AUTOSAR XML (schema 4-0-3)
package /Svc_IoHwAb/CompuMethods
  compu method IoHwAb_Cm_EdgeEnum: 1=IOHWAB_RISING_EDGE (IoHwAb_RisingEdge), 2=IOHWAB_FALLING_EDGE (IoHwAb_FallingEdge), 3=IOHWAB_BOTH_EDGES (IoHwAb_BothEdges)
package /Svc_IoHwAb/ImplementationDataTypes
  19 x impl type:
    IoHwAb_LevelType: category=VALUE, base-type=uint8, compu {0=IOHWAB_LOW (IoHwAb_Low), 1=IOHWAB_HIGH (IoHwAb_High)}
    IoHwAb_ThresholdType: category=VALUE, base-type=uint8
    IoHwAb_IndexType: category=VALUE, base-type=uint16
    IoHwAb_PwmEdgeType: category=VALUE, base-type=uint8, compu-method=IoHwAb_Cm_EdgeEnum
    IoHwAb_GptValueType: category=VALUE, base-type=uint32
    IoHwAb_IcuActivationType: category=VALUE, base-type=uint8, compu-method=IoHwAb_Cm_EdgeEnum
    IoHwAb_ValueType: category=VALUE, base-type=uint16
    IoHwAb_IcuEdgeNumberType: category=VALUE, base-type=uint32
    IoHwAb_IcuStateType: category=VALUE, base-type=uint8, compu {0=IOHWAB_IDLE (IoHwAb_Idle), 1=IOHWAB_ACTIVE (IoHwAb_Active)}
    IoHwAb_OcuValueType: category=VALUE, base-type=uint16
    IoHwAb_OcuPinActionType: category=VALUE, base-type=uint8
    IoHwAb_OcuPinStateType: category=VALUE, base-type=uint8
    IoHwAb_LengthType: category=VALUE, base-type=uint8
    IoHwAb_IcuIndexType: category=VALUE, base-type=uint16
    IoHwAb_PwmPeriodType: category=VALUE, base-type=uint32
    IoHwAb_OcuReturnType: category=VALUE, base-type=uint8
    IoHwAb_BoolType: category=VALUE, base-type=uint8, compu {0=IOHWAB_FALSE (IoHwAb_False), 1=IOHWAB_TRUE (IoHwAb_True)}
    IoHwAb_IcuValueType: category=VALUE, base-type=uint32
    IoHwAb_IcuDutyCycleType: category=STRUCTURE
      element ActiveTime: implementation-data-type=IoHwAb_IcuValueType
      element PeriodTime: implementation-data-type=IoHwAb_IcuValueType
package /Svc_IoHwAb/ClientServerInterfaces
  4 x client server interface, all with is-service=true:
    IoHwAb_If_DigDir
      6 x operation:
        ReadDirect
          arg Level: type=IoHwAb_LevelType, direction=OUT, server-argument-impl-policy=USE-ARGUMENT-TYPE
        WriteDirect
          arg Level: type=IoHwAb_LevelType, direction=IN, server-argument-impl-policy=USE-ARGUMENT-TYPE
        SetToInput
        SetToOutput
        IsInput
          arg blResult: type=IoHwAb_BoolType, direction=OUT, server-argument-impl-policy=USE-ARGUMENT-TYPE
        IsOutput
          arg blResult: type=IoHwAb_BoolType, direction=OUT, server-argument-impl-policy=USE-ARGUMENT-TYPE
    IoHwAb_If_AnaInDir
      operation ReadDirect: possible-error=[E_BUSY, E_WRONG_LENGTH, E_SETUP_BUFFER_FAIL]
        arg Value: type=IoHwAb_ValueType, direction=OUT, server-argument-impl-policy=USE-ARGUMENT-TYPE
        arg AnaInDirLength: type=IoHwAb_LengthType, direction=IN, server-argument-impl-policy=USE-ARGUMENT-TYPE
      error E_BUSY: error-code=4
      error E_WRONG_LENGTH: error-code=5
      error E_SETUP_BUFFER_FAIL: error-code=6
    IoHwAb_If_Gpt
      7 x operation:
        StartTimer: possible-error=IoHwAb_If_Gpt/E_NOT_SUPPORTED
          arg Value: type=IoHwAb_GptValueType, direction=IN, server-argument-impl-policy=USE-ARGUMENT-TYPE
        StopTimer: possible-error=IoHwAb_If_Gpt/E_NOT_SUPPORTED
        GetTimeElapsed: possible-error=IoHwAb_If_Gpt/E_NOT_SUPPORTED
          arg Value: type=IoHwAb_GptValueType, direction=OUT, server-argument-impl-policy=USE-ARGUMENT-TYPE
        GetTimeRemaining: possible-error=IoHwAb_If_Gpt/E_NOT_SUPPORTED
          arg Value: type=IoHwAb_GptValueType, direction=OUT, server-argument-impl-policy=USE-ARGUMENT-TYPE
        DisableNotification: possible-error=IoHwAb_If_Gpt/E_NOT_SUPPORTED
        EnableNotification: possible-error=IoHwAb_If_Gpt/E_NOT_SUPPORTED
        Notification
      error E_NOT_SUPPORTED: error-code=10
    IoHwAb_If_Pwm
      6 x operation, all with possible-error=IoHwAb_If_Pwm/E_NOT_SUPPORTED:
        SetDutyCycle
          arg Duty: type=uint16, direction=IN, server-argument-impl-policy=USE-ARGUMENT-TYPE
        SetPeriodAndDuty
          arg Period: type=IoHwAb_PwmPeriodType, direction=IN, server-argument-impl-policy=USE-ARGUMENT-TYPE
          arg Duty: type=uint16, direction=IN, server-argument-impl-policy=USE-ARGUMENT-TYPE
        SetOutputToIdle
        GetOutputState
          arg Level: type=IoHwAb_LevelType, direction=OUT, server-argument-impl-policy=USE-ARGUMENT-TYPE
        DisableNotification
        EnableNotification
          arg NotificationEdge: type=IoHwAb_PwmEdgeType, direction=IN, server-argument-impl-policy=USE-ARGUMENT-TYPE
      error E_NOT_SUPPORTED: error-code=11
package /Svc_IoHwAb/EcuAbstractionSwComponentTypes
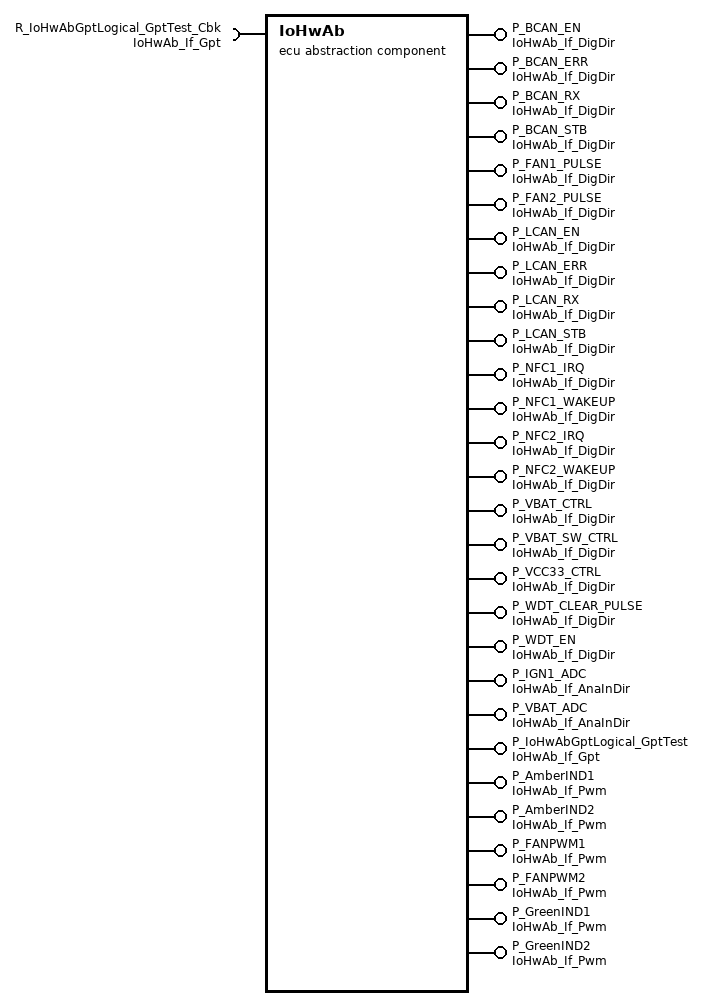
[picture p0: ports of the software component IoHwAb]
  ecu abstraction sw component type IoHwAb
    22 x provide port:
      P_BCAN_EN: provided-interface=IoHwAb_If_DigDir
        provided-com-specs:
          operation=IoHwAb_If_DigDir/ReadDirect, queue-length=1
          operation=WriteDirect, queue-length=1
          operation=SetToInput, queue-length=1
          operation=SetToOutput, queue-length=1
          operation=IsInput, queue-length=1
          operation=IsOutput, queue-length=1
      P_BCAN_ERR: provided-interface=IoHwAb_If_DigDir
        provided-com-specs:
          operation=IoHwAb_If_DigDir/ReadDirect, queue-length=1
          operation=WriteDirect, queue-length=1
          operation=SetToInput, queue-length=1
          operation=SetToOutput, queue-length=1
          operation=IsInput, queue-length=1
          operation=IsOutput, queue-length=1
      P_BCAN_RX: provided-interface=IoHwAb_If_DigDir
        provided-com-specs:
          operation=IoHwAb_If_DigDir/ReadDirect, queue-length=1
          operation=WriteDirect, queue-length=1
          operation=SetToInput, queue-length=1
          operation=SetToOutput, queue-length=1
          operation=IsInput, queue-length=1
          operation=IsOutput, queue-length=1
      P_BCAN_STB: provided-interface=IoHwAb_If_DigDir
        provided-com-specs:
          operation=IoHwAb_If_DigDir/ReadDirect, queue-length=1
          operation=WriteDirect, queue-length=1
          operation=SetToInput, queue-length=1
          operation=SetToOutput, queue-length=1
          operation=IsInput, queue-length=1
          operation=IsOutput, queue-length=1
      P_FAN1_PULSE: provided-interface=IoHwAb_If_DigDir
        provided-com-specs:
          operation=IoHwAb_If_DigDir/ReadDirect, queue-length=1
          operation=WriteDirect, queue-length=1
          operation=SetToInput, queue-length=1
          operation=SetToOutput, queue-length=1
          operation=IsInput, queue-length=1
          operation=IsOutput, queue-length=1
      P_FAN2_PULSE: provided-interface=IoHwAb_If_DigDir
        provided-com-specs:
          operation=IoHwAb_If_DigDir/ReadDirect, queue-length=1
          operation=WriteDirect, queue-length=1
          operation=SetToInput, queue-length=1
          operation=SetToOutput, queue-length=1
          operation=IsInput, queue-length=1
          operation=IsOutput, queue-length=1
      P_LCAN_EN: provided-interface=IoHwAb_If_DigDir
        provided-com-specs:
          operation=IoHwAb_If_DigDir/ReadDirect, queue-length=1
          operation=WriteDirect, queue-length=1
          operation=SetToInput, queue-length=1
          operation=SetToOutput, queue-length=1
          operation=IsInput, queue-length=1
          operation=IsOutput, queue-length=1
      P_LCAN_ERR: provided-interface=IoHwAb_If_DigDir
        provided-com-specs:
          operation=IoHwAb_If_DigDir/ReadDirect, queue-length=1
          operation=WriteDirect, queue-length=1
          operation=SetToInput, queue-length=1
          operation=SetToOutput, queue-length=1
          operation=IsInput, queue-length=1
          operation=IsOutput, queue-length=1
      P_LCAN_RX: provided-interface=IoHwAb_If_DigDir
        provided-com-specs:
          operation=IoHwAb_If_DigDir/ReadDirect, queue-length=1
          operation=WriteDirect, queue-length=1
          operation=SetToInput, queue-length=1
          operation=SetToOutput, queue-length=1
          operation=IsInput, queue-length=1
          operation=IsOutput, queue-length=1
      P_LCAN_STB: provided-interface=IoHwAb_If_DigDir
        provided-com-specs:
          operation=IoHwAb_If_DigDir/ReadDirect, queue-length=1
          operation=WriteDirect, queue-length=1
          operation=SetToInput, queue-length=1
          operation=SetToOutput, queue-length=1
          operation=IsInput, queue-length=1
          operation=IsOutput, queue-length=1
      P_NFC1_IRQ: provided-interface=IoHwAb_If_DigDir
        provided-com-specs:
          operation=IoHwAb_If_DigDir/ReadDirect, queue-length=1
          operation=WriteDirect, queue-length=1
          operation=SetToInput, queue-length=1
          operation=SetToOutput, queue-length=1
          operation=IsInput, queue-length=1
          operation=IsOutput, queue-length=1
      P_NFC1_WAKEUP: provided-interface=IoHwAb_If_DigDir
        provided-com-specs:
          operation=IoHwAb_If_DigDir/ReadDirect, queue-length=1
          operation=WriteDirect, queue-length=1
          operation=SetToInput, queue-length=1
          operation=SetToOutput, queue-length=1
          operation=IsInput, queue-length=1
          operation=IsOutput, queue-length=1
      P_NFC2_IRQ: provided-interface=IoHwAb_If_DigDir
        provided-com-specs:
          operation=IoHwAb_If_DigDir/ReadDirect, queue-length=1
          operation=WriteDirect, queue-length=1
          operation=SetToInput, queue-length=1
          operation=SetToOutput, queue-length=1
          operation=IsInput, queue-length=1
          operation=IsOutput, queue-length=1
      P_NFC2_WAKEUP: provided-interface=IoHwAb_If_DigDir
        provided-com-specs:
          operation=IoHwAb_If_DigDir/ReadDirect, queue-length=1
          operation=WriteDirect, queue-length=1
          operation=SetToInput, queue-length=1
          operation=SetToOutput, queue-length=1
          operation=IsInput, queue-length=1
          operation=IsOutput, queue-length=1
      P_VBAT_CTRL: provided-interface=IoHwAb_If_DigDir
        provided-com-specs:
          operation=IoHwAb_If_DigDir/ReadDirect, queue-length=1
          operation=WriteDirect, queue-length=1
          operation=SetToInput, queue-length=1
          operation=SetToOutput, queue-length=1
          operation=IsInput, queue-length=1
          operation=IsOutput, queue-length=1
      P_VBAT_SW_CTRL: provided-interface=IoHwAb_If_DigDir
        provided-com-specs:
          operation=IoHwAb_If_DigDir/ReadDirect, queue-length=1
          operation=WriteDirect, queue-length=1
          operation=SetToInput, queue-length=1
          operation=SetToOutput, queue-length=1
          operation=IsInput, queue-length=1
          operation=IsOutput, queue-length=1
      P_VCC33_CTRL: provided-interface=IoHwAb_If_DigDir
        provided-com-specs:
          operation=IoHwAb_If_DigDir/ReadDirect, queue-length=1
          operation=WriteDirect, queue-length=1
          operation=SetToInput, queue-length=1
          operation=SetToOutput, queue-length=1
          operation=IsInput, queue-length=1
          operation=IsOutput, queue-length=1
      P_WDT_CLEAR_PULSE: provided-interface=IoHwAb_If_DigDir
        provided-com-specs:
          operation=IoHwAb_If_DigDir/ReadDirect, queue-length=1
          operation=WriteDirect, queue-length=1
          operation=SetToInput, queue-length=1
          operation=SetToOutput, queue-length=1
          operation=IsInput, queue-length=1
          operation=IsOutput, queue-length=1
      P_WDT_EN: provided-interface=IoHwAb_If_DigDir
        provided-com-specs:
          operation=IoHwAb_If_DigDir/ReadDirect, queue-length=1
          operation=WriteDirect, queue-length=1
          operation=SetToInput, queue-length=1
          operation=SetToOutput, queue-length=1
          operation=IsInput, queue-length=1
          operation=IsOutput, queue-length=1
      P_IGN1_ADC: server-com-spec{operation=IoHwAb_If_AnaInDir/ReadDirect, queue-length=1}, provided-interface=IoHwAb_If_AnaInDir
      P_VBAT_ADC: server-com-spec{operation=IoHwAb_If_AnaInDir/ReadDirect, queue-length=1}, provided-interface=IoHwAb_If_AnaInDir
      P_IoHwAbGptLogical_GptTest: provided-interface=IoHwAb_If_Gpt
        provided-com-specs:
          operation=StartTimer, queue-length=1
          operation=StopTimer, queue-length=1
          operation=GetTimeElapsed, queue-length=1
          operation=GetTimeRemaining, queue-length=1
          operation=IoHwAb_If_Gpt/DisableNotification, queue-length=1
          operation=IoHwAb_If_Gpt/EnableNotification, queue-length=1
    require port R_IoHwAbGptLogical_GptTest_Cbk: client-com-spec=Notification, required-interface=IoHwAb_If_Gpt
    6 x provide port, all with provided-interface=IoHwAb_If_Pwm:
      P_AmberIND1
        provided-com-specs:
          operation=SetDutyCycle, queue-length=1
          operation=SetPeriodAndDuty, queue-length=1
          operation=SetOutputToIdle, queue-length=1
          operation=GetOutputState, queue-length=1
          operation=IoHwAb_If_Pwm/DisableNotification, queue-length=1
          operation=IoHwAb_If_Pwm/EnableNotification, queue-length=1
      P_AmberIND2
        provided-com-specs:
          operation=SetDutyCycle, queue-length=1
          operation=SetPeriodAndDuty, queue-length=1
          operation=SetOutputToIdle, queue-length=1
          operation=GetOutputState, queue-length=1
          operation=IoHwAb_If_Pwm/DisableNotification, queue-length=1
          operation=IoHwAb_If_Pwm/EnableNotification, queue-length=1
      P_FANPWM1
        provided-com-specs:
          operation=SetDutyCycle, queue-length=1
          operation=SetPeriodAndDuty, queue-length=1
          operation=SetOutputToIdle, queue-length=1
          operation=GetOutputState, queue-length=1
          operation=IoHwAb_If_Pwm/DisableNotification, queue-length=1
          operation=IoHwAb_If_Pwm/EnableNotification, queue-length=1
      P_FANPWM2
        provided-com-specs:
          operation=SetDutyCycle, queue-length=1
          operation=SetPeriodAndDuty, queue-length=1
          operation=SetOutputToIdle, queue-length=1
          operation=GetOutputState, queue-length=1
          operation=IoHwAb_If_Pwm/DisableNotification, queue-length=1
          operation=IoHwAb_If_Pwm/EnableNotification, queue-length=1
      P_GreenIND1
        provided-com-specs:
          operation=SetDutyCycle, queue-length=1
          operation=SetPeriodAndDuty, queue-length=1
          operation=SetOutputToIdle, queue-length=1
          operation=GetOutputState, queue-length=1
          operation=IoHwAb_If_Pwm/DisableNotification, queue-length=1
          operation=IoHwAb_If_Pwm/EnableNotification, queue-length=1
      P_GreenIND2
        provided-com-specs:
          operation=SetDutyCycle, queue-length=1
          operation=SetPeriodAndDuty, queue-length=1
          operation=SetOutputToIdle, queue-length=1
          operation=GetOutputState, queue-length=1
          operation=IoHwAb_If_Pwm/DisableNotification, queue-length=1
          operation=IoHwAb_If_Pwm/EnableNotification, queue-length=1
    behavior IB_IoHwAb
      158 x operation invoked event:
        IoHwAb_Ev_BCAN_EN_ReadDirect: start-on-event=IoHwAb_Re_DigDir_ReadDirect, operation=P_BCAN_EN.ReadDirect
        IoHwAb_Ev_BCAN_EN_WriteDirect: start-on-event=IoHwAb_Re_DigDir_WriteDirect, operation=P_BCAN_EN.WriteDirect
        IoHwAb_Ev_BCAN_EN_SetToInput: start-on-event=IoHwAb_Re_DigDir_SetToInput, operation=P_BCAN_EN.SetToInput
        IoHwAb_Ev_BCAN_EN_SetToOutput: start-on-event=IoHwAb_Re_DigDir_SetToOutput, operation=P_BCAN_EN.SetToOutput
        IoHwAb_Ev_BCAN_EN_IsInput: start-on-event=IoHwAb_Re_DigDir_IsInput, operation=P_BCAN_EN.IsInput
        IoHwAb_Ev_BCAN_EN_IsOutput: start-on-event=IoHwAb_Re_DigDir_IsOutput, operation=P_BCAN_EN.IsOutput
        IoHwAb_Ev_BCAN_ERR_ReadDirect: start-on-event=IoHwAb_Re_DigDir_ReadDirect, operation=P_BCAN_ERR.ReadDirect
        IoHwAb_Ev_BCAN_ERR_WriteDirect: start-on-event=IoHwAb_Re_DigDir_WriteDirect, operation=P_BCAN_ERR.WriteDirect
        IoHwAb_Ev_BCAN_ERR_SetToInput: start-on-event=IoHwAb_Re_DigDir_SetToInput, operation=P_BCAN_ERR.SetToInput
        IoHwAb_Ev_BCAN_ERR_SetToOutput: start-on-event=IoHwAb_Re_DigDir_SetToOutput, operation=P_BCAN_ERR.SetToOutput
        IoHwAb_Ev_BCAN_ERR_IsInput: start-on-event=IoHwAb_Re_DigDir_IsInput, operation=P_BCAN_ERR.IsInput
        IoHwAb_Ev_BCAN_ERR_IsOutput: start-on-event=IoHwAb_Re_DigDir_IsOutput, operation=P_BCAN_ERR.IsOutput
        IoHwAb_Ev_BCAN_RX_ReadDirect: start-on-event=IoHwAb_Re_DigDir_ReadDirect, operation=P_BCAN_RX.ReadDirect
        IoHwAb_Ev_BCAN_RX_WriteDirect: start-on-event=IoHwAb_Re_DigDir_WriteDirect, operation=P_BCAN_RX.WriteDirect
        IoHwAb_Ev_BCAN_RX_SetToInput: start-on-event=IoHwAb_Re_DigDir_SetToInput, operation=P_BCAN_RX.SetToInput
        IoHwAb_Ev_BCAN_RX_SetToOutput: start-on-event=IoHwAb_Re_DigDir_SetToOutput, operation=P_BCAN_RX.SetToOutput
        IoHwAb_Ev_BCAN_RX_IsInput: start-on-event=IoHwAb_Re_DigDir_IsInput, operation=P_BCAN_RX.IsInput
        IoHwAb_Ev_BCAN_RX_IsOutput: start-on-event=IoHwAb_Re_DigDir_IsOutput, operation=P_BCAN_RX.IsOutput
        IoHwAb_Ev_BCAN_STB_ReadDirect: start-on-event=IoHwAb_Re_DigDir_ReadDirect, operation=P_BCAN_STB.ReadDirect
        IoHwAb_Ev_BCAN_STB_WriteDirect: start-on-event=IoHwAb_Re_DigDir_WriteDirect, operation=P_BCAN_STB.WriteDirect
        IoHwAb_Ev_BCAN_STB_SetToInput: start-on-event=IoHwAb_Re_DigDir_SetToInput, operation=P_BCAN_STB.SetToInput
        IoHwAb_Ev_BCAN_STB_SetToOutput: start-on-event=IoHwAb_Re_DigDir_SetToOutput, operation=P_BCAN_STB.SetToOutput
        IoHwAb_Ev_BCAN_STB_IsInput: start-on-event=IoHwAb_Re_DigDir_IsInput, operation=P_BCAN_STB.IsInput
        IoHwAb_Ev_BCAN_STB_IsOutput: start-on-event=IoHwAb_Re_DigDir_IsOutput, operation=P_BCAN_STB.IsOutput
        IoHwAb_Ev_FAN1_PULSE_ReadDirect: start-on-event=IoHwAb_Re_DigDir_ReadDirect, operation=P_FAN1_PULSE.ReadDirect
        IoHwAb_Ev_FAN1_PULSE_WriteDirect: start-on-event=IoHwAb_Re_DigDir_WriteDirect, operation=P_FAN1_PULSE.WriteDirect
        IoHwAb_Ev_FAN1_PULSE_SetToInput: start-on-event=IoHwAb_Re_DigDir_SetToInput, operation=P_FAN1_PULSE.SetToInput
        IoHwAb_Ev_FAN1_PULSE_SetToOutput: start-on-event=IoHwAb_Re_DigDir_SetToOutput, operation=P_FAN1_PULSE.SetToOutput
        IoHwAb_Ev_FAN1_PULSE_IsInput: start-on-event=IoHwAb_Re_DigDir_IsInput, operation=P_FAN1_PULSE.IsInput
        IoHwAb_Ev_FAN1_PULSE_IsOutput: start-on-event=IoHwAb_Re_DigDir_IsOutput, operation=P_FAN1_PULSE.IsOutput
        IoHwAb_Ev_FAN2_PULSE_ReadDirect: start-on-event=IoHwAb_Re_DigDir_ReadDirect, operation=P_FAN2_PULSE.ReadDirect
        IoHwAb_Ev_FAN2_PULSE_WriteDirect: start-on-event=IoHwAb_Re_DigDir_WriteDirect, operation=P_FAN2_PULSE.WriteDirect
        IoHwAb_Ev_FAN2_PULSE_SetToInput: start-on-event=IoHwAb_Re_DigDir_SetToInput, operation=P_FAN2_PULSE.SetToInput
        IoHwAb_Ev_FAN2_PULSE_SetToOutput: start-on-event=IoHwAb_Re_DigDir_SetToOutput, operation=P_FAN2_PULSE.SetToOutput
        IoHwAb_Ev_FAN2_PULSE_IsInput: start-on-event=IoHwAb_Re_DigDir_IsInput, operation=P_FAN2_PULSE.IsInput
        IoHwAb_Ev_FAN2_PULSE_IsOutput: start-on-event=IoHwAb_Re_DigDir_IsOutput, operation=P_FAN2_PULSE.IsOutput
        IoHwAb_Ev_LCAN_EN_ReadDirect: start-on-event=IoHwAb_Re_DigDir_ReadDirect, operation=P_LCAN_EN.ReadDirect
        IoHwAb_Ev_LCAN_EN_WriteDirect: start-on-event=IoHwAb_Re_DigDir_WriteDirect, operation=P_LCAN_EN.WriteDirect
        IoHwAb_Ev_LCAN_EN_SetToInput: start-on-event=IoHwAb_Re_DigDir_SetToInput, operation=P_LCAN_EN.SetToInput
        IoHwAb_Ev_LCAN_EN_SetToOutput: start-on-event=IoHwAb_Re_DigDir_SetToOutput, operation=P_LCAN_EN.SetToOutput
        IoHwAb_Ev_LCAN_EN_IsInput: start-on-event=IoHwAb_Re_DigDir_IsInput, operation=P_LCAN_EN.IsInput
        IoHwAb_Ev_LCAN_EN_IsOutput: start-on-event=IoHwAb_Re_DigDir_IsOutput, operation=P_LCAN_EN.IsOutput
        IoHwAb_Ev_LCAN_ERR_ReadDirect: start-on-event=IoHwAb_Re_DigDir_ReadDirect, operation=P_LCAN_ERR.ReadDirect
        IoHwAb_Ev_LCAN_ERR_WriteDirect: start-on-event=IoHwAb_Re_DigDir_WriteDirect, operation=P_LCAN_ERR.WriteDirect
        IoHwAb_Ev_LCAN_ERR_SetToInput: start-on-event=IoHwAb_Re_DigDir_SetToInput, operation=P_LCAN_ERR.SetToInput
        IoHwAb_Ev_LCAN_ERR_SetToOutput: start-on-event=IoHwAb_Re_DigDir_SetToOutput, operation=P_LCAN_ERR.SetToOutput
        IoHwAb_Ev_LCAN_ERR_IsInput: start-on-event=IoHwAb_Re_DigDir_IsInput, operation=P_LCAN_ERR.IsInput
        IoHwAb_Ev_LCAN_ERR_IsOutput: start-on-event=IoHwAb_Re_DigDir_IsOutput, operation=P_LCAN_ERR.IsOutput
        IoHwAb_Ev_LCAN_RX_ReadDirect: start-on-event=IoHwAb_Re_DigDir_ReadDirect, operation=P_LCAN_RX.ReadDirect
        IoHwAb_Ev_LCAN_RX_WriteDirect: start-on-event=IoHwAb_Re_DigDir_WriteDirect, operation=P_LCAN_RX.WriteDirect
        IoHwAb_Ev_LCAN_RX_SetToInput: start-on-event=IoHwAb_Re_DigDir_SetToInput, operation=P_LCAN_RX.SetToInput
        IoHwAb_Ev_LCAN_RX_SetToOutput: start-on-event=IoHwAb_Re_DigDir_SetToOutput, operation=P_LCAN_RX.SetToOutput
        IoHwAb_Ev_LCAN_RX_IsInput: start-on-event=IoHwAb_Re_DigDir_IsInput, operation=P_LCAN_RX.IsInput
        IoHwAb_Ev_LCAN_RX_IsOutput: start-on-event=IoHwAb_Re_DigDir_IsOutput, operation=P_LCAN_RX.IsOutput
        IoHwAb_Ev_LCAN_STB_ReadDirect: start-on-event=IoHwAb_Re_DigDir_ReadDirect, operation=P_LCAN_STB.ReadDirect
        IoHwAb_Ev_LCAN_STB_WriteDirect: start-on-event=IoHwAb_Re_DigDir_WriteDirect, operation=P_LCAN_STB.WriteDirect
        IoHwAb_Ev_LCAN_STB_SetToInput: start-on-event=IoHwAb_Re_DigDir_SetToInput, operation=P_LCAN_STB.SetToInput
        IoHwAb_Ev_LCAN_STB_SetToOutput: start-on-event=IoHwAb_Re_DigDir_SetToOutput, operation=P_LCAN_STB.SetToOutput
        IoHwAb_Ev_LCAN_STB_IsInput: start-on-event=IoHwAb_Re_DigDir_IsInput, operation=P_LCAN_STB.IsInput
        IoHwAb_Ev_LCAN_STB_IsOutput: start-on-event=IoHwAb_Re_DigDir_IsOutput, operation=P_LCAN_STB.IsOutput
        IoHwAb_Ev_NFC1_IRQ_ReadDirect: start-on-event=IoHwAb_Re_DigDir_ReadDirect, operation=P_NFC1_IRQ.ReadDirect
        IoHwAb_Ev_NFC1_IRQ_WriteDirect: start-on-event=IoHwAb_Re_DigDir_WriteDirect, operation=P_NFC1_IRQ.WriteDirect
        IoHwAb_Ev_NFC1_IRQ_SetToInput: start-on-event=IoHwAb_Re_DigDir_SetToInput, operation=P_NFC1_IRQ.SetToInput
        IoHwAb_Ev_NFC1_IRQ_SetToOutput: start-on-event=IoHwAb_Re_DigDir_SetToOutput, operation=P_NFC1_IRQ.SetToOutput
        IoHwAb_Ev_NFC1_IRQ_IsInput: start-on-event=IoHwAb_Re_DigDir_IsInput, operation=P_NFC1_IRQ.IsInput
        IoHwAb_Ev_NFC1_IRQ_IsOutput: start-on-event=IoHwAb_Re_DigDir_IsOutput, operation=P_NFC1_IRQ.IsOutput
        IoHwAb_Ev_NFC1_WAKEUP_ReadDirect: start-on-event=IoHwAb_Re_DigDir_ReadDirect, operation=P_NFC1_WAKEUP.ReadDirect
        IoHwAb_Ev_NFC1_WAKEUP_WriteDirect: start-on-event=IoHwAb_Re_DigDir_WriteDirect, operation=P_NFC1_WAKEUP.WriteDirect
        IoHwAb_Ev_NFC1_WAKEUP_SetToInput: start-on-event=IoHwAb_Re_DigDir_SetToInput, operation=P_NFC1_WAKEUP.SetToInput
        IoHwAb_Ev_NFC1_WAKEUP_SetToOutput: start-on-event=IoHwAb_Re_DigDir_SetToOutput, operation=P_NFC1_WAKEUP.SetToOutput
        IoHwAb_Ev_NFC1_WAKEUP_IsInput: start-on-event=IoHwAb_Re_DigDir_IsInput, operation=P_NFC1_WAKEUP.IsInput
        IoHwAb_Ev_NFC1_WAKEUP_IsOutput: start-on-event=IoHwAb_Re_DigDir_IsOutput, operation=P_NFC1_WAKEUP.IsOutput
        IoHwAb_Ev_NFC2_IRQ_ReadDirect: start-on-event=IoHwAb_Re_DigDir_ReadDirect, operation=P_NFC2_IRQ.ReadDirect
        IoHwAb_Ev_NFC2_IRQ_WriteDirect: start-on-event=IoHwAb_Re_DigDir_WriteDirect, operation=P_NFC2_IRQ.WriteDirect
        IoHwAb_Ev_NFC2_IRQ_SetToInput: start-on-event=IoHwAb_Re_DigDir_SetToInput, operation=P_NFC2_IRQ.SetToInput
        IoHwAb_Ev_NFC2_IRQ_SetToOutput: start-on-event=IoHwAb_Re_DigDir_SetToOutput, operation=P_NFC2_IRQ.SetToOutput
        IoHwAb_Ev_NFC2_IRQ_IsInput: start-on-event=IoHwAb_Re_DigDir_IsInput, operation=P_NFC2_IRQ.IsInput
        IoHwAb_Ev_NFC2_IRQ_IsOutput: start-on-event=IoHwAb_Re_DigDir_IsOutput, operation=P_NFC2_IRQ.IsOutput
        IoHwAb_Ev_NFC2_WAKEUP_ReadDirect: start-on-event=IoHwAb_Re_DigDir_ReadDirect, operation=P_NFC2_WAKEUP.ReadDirect
        IoHwAb_Ev_NFC2_WAKEUP_WriteDirect: start-on-event=IoHwAb_Re_DigDir_WriteDirect, operation=P_NFC2_WAKEUP.WriteDirect
        IoHwAb_Ev_NFC2_WAKEUP_SetToInput: start-on-event=IoHwAb_Re_DigDir_SetToInput, operation=P_NFC2_WAKEUP.SetToInput
        IoHwAb_Ev_NFC2_WAKEUP_SetToOutput: start-on-event=IoHwAb_Re_DigDir_SetToOutput, operation=P_NFC2_WAKEUP.SetToOutput
        IoHwAb_Ev_NFC2_WAKEUP_IsInput: start-on-event=IoHwAb_Re_DigDir_IsInput, operation=P_NFC2_WAKEUP.IsInput
        IoHwAb_Ev_NFC2_WAKEUP_IsOutput: start-on-event=IoHwAb_Re_DigDir_IsOutput, operation=P_NFC2_WAKEUP.IsOutput
        IoHwAb_Ev_VBAT_CTRL_ReadDirect: start-on-event=IoHwAb_Re_DigDir_ReadDirect, operation=P_VBAT_CTRL.ReadDirect
        IoHwAb_Ev_VBAT_CTRL_WriteDirect: start-on-event=IoHwAb_Re_DigDir_WriteDirect, operation=P_VBAT_CTRL.WriteDirect
        IoHwAb_Ev_VBAT_CTRL_SetToInput: start-on-event=IoHwAb_Re_DigDir_SetToInput, operation=P_VBAT_CTRL.SetToInput
        IoHwAb_Ev_VBAT_CTRL_SetToOutput: start-on-event=IoHwAb_Re_DigDir_SetToOutput, operation=P_VBAT_CTRL.SetToOutput
        IoHwAb_Ev_VBAT_CTRL_IsInput: start-on-event=IoHwAb_Re_DigDir_IsInput, operation=P_VBAT_CTRL.IsInput
        IoHwAb_Ev_VBAT_CTRL_IsOutput: start-on-event=IoHwAb_Re_DigDir_IsOutput, operation=P_VBAT_CTRL.IsOutput
        IoHwAb_Ev_VBAT_SW_CTRL_ReadDirect: start-on-event=IoHwAb_Re_DigDir_ReadDirect, operation=P_VBAT_SW_CTRL.ReadDirect
        IoHwAb_Ev_VBAT_SW_CTRL_WriteDirect: start-on-event=IoHwAb_Re_DigDir_WriteDirect, operation=P_VBAT_SW_CTRL.WriteDirect
        IoHwAb_Ev_VBAT_SW_CTRL_SetToInput: start-on-event=IoHwAb_Re_DigDir_SetToInput, operation=P_VBAT_SW_CTRL.SetToInput
        IoHwAb_Ev_VBAT_SW_CTRL_SetToOutput: start-on-event=IoHwAb_Re_DigDir_SetToOutput, operation=P_VBAT_SW_CTRL.SetToOutput
        IoHwAb_Ev_VBAT_SW_CTRL_IsInput: start-on-event=IoHwAb_Re_DigDir_IsInput, operation=P_VBAT_SW_CTRL.IsInput
        IoHwAb_Ev_VBAT_SW_CTRL_IsOutput: start-on-event=IoHwAb_Re_DigDir_IsOutput, operation=P_VBAT_SW_CTRL.IsOutput
        IoHwAb_Ev_VCC33_CTRL_ReadDirect: start-on-event=IoHwAb_Re_DigDir_ReadDirect, operation=P_VCC33_CTRL.ReadDirect
        IoHwAb_Ev_VCC33_CTRL_WriteDirect: start-on-event=IoHwAb_Re_DigDir_WriteDirect, operation=P_VCC33_CTRL.WriteDirect
        IoHwAb_Ev_VCC33_CTRL_SetToInput: start-on-event=IoHwAb_Re_DigDir_SetToInput, operation=P_VCC33_CTRL.SetToInput
        IoHwAb_Ev_VCC33_CTRL_SetToOutput: start-on-event=IoHwAb_Re_DigDir_SetToOutput, operation=P_VCC33_CTRL.SetToOutput
        IoHwAb_Ev_VCC33_CTRL_IsInput: start-on-event=IoHwAb_Re_DigDir_IsInput, operation=P_VCC33_CTRL.IsInput
        IoHwAb_Ev_VCC33_CTRL_IsOutput: start-on-event=IoHwAb_Re_DigDir_IsOutput, operation=P_VCC33_CTRL.IsOutput
        IoHwAb_Ev_WDT_CLEAR_PULSE_ReadDirect: start-on-event=IoHwAb_Re_DigDir_ReadDirect, operation=P_WDT_CLEAR_PULSE.ReadDirect
        IoHwAb_Ev_WDT_CLEAR_PULSE_WriteDirect: start-on-event=IoHwAb_Re_DigDir_WriteDirect, operation=P_WDT_CLEAR_PULSE.WriteDirect
        IoHwAb_Ev_WDT_CLEAR_PULSE_SetToInput: start-on-event=IoHwAb_Re_DigDir_SetToInput, operation=P_WDT_CLEAR_PULSE.SetToInput
        IoHwAb_Ev_WDT_CLEAR_PULSE_SetToOutput: start-on-event=IoHwAb_Re_DigDir_SetToOutput, operation=P_WDT_CLEAR_PULSE.SetToOutput
        IoHwAb_Ev_WDT_CLEAR_PULSE_IsInput: start-on-event=IoHwAb_Re_DigDir_IsInput, operation=P_WDT_CLEAR_PULSE.IsInput
        IoHwAb_Ev_WDT_CLEAR_PULSE_IsOutput: start-on-event=IoHwAb_Re_DigDir_IsOutput, operation=P_WDT_CLEAR_PULSE.IsOutput
        IoHwAb_Ev_WDT_EN_ReadDirect: start-on-event=IoHwAb_Re_DigDir_ReadDirect, operation=P_WDT_EN.ReadDirect
        IoHwAb_Ev_WDT_EN_WriteDirect: start-on-event=IoHwAb_Re_DigDir_WriteDirect, operation=P_WDT_EN.WriteDirect
        IoHwAb_Ev_WDT_EN_SetToInput: start-on-event=IoHwAb_Re_DigDir_SetToInput, operation=P_WDT_EN.SetToInput
        IoHwAb_Ev_WDT_EN_SetToOutput: start-on-event=IoHwAb_Re_DigDir_SetToOutput, operation=P_WDT_EN.SetToOutput
        IoHwAb_Ev_WDT_EN_IsInput: start-on-event=IoHwAb_Re_DigDir_IsInput, operation=P_WDT_EN.IsInput
        IoHwAb_Ev_WDT_EN_IsOutput: start-on-event=IoHwAb_Re_DigDir_IsOutput, operation=P_WDT_EN.IsOutput
        IoHwAb_Ev_IGN1_ADC_ReadDirect: start-on-event=IoHwAb_Re_AnaInDir_ReadDirect, operation=P_IGN1_ADC.ReadDirect
        IoHwAb_Ev_VBAT_ADC_ReadDirect: start-on-event=IoHwAb_Re_AnaInDir_ReadDirect, operation=P_VBAT_ADC.ReadDirect
        IoHwAb_Ev_IoHwAbGptLogical_GptTest_StartTimer: start-on-event=IoHwAb_Re_Gpt_StartTimer, operation=P_IoHwAbGptLogical_GptTest.StartTimer
        IoHwAb_Ev_IoHwAbGptLogical_GptTest_StopTimer: start-on-event=IoHwAb_Re_Gpt_StopTimer, operation=P_IoHwAbGptLogical_GptTest.StopTimer
        IoHwAb_Ev_IoHwAbGptLogical_GptTest_GetTimeElapsed: start-on-event=IoHwAb_Re_Gpt_GetTimeElapsed, operation=P_IoHwAbGptLogical_GptTest.GetTimeElapsed
        IoHwAb_Ev_IoHwAbGptLogical_GptTest_GetTimeRemaining: start-on-event=IoHwAb_Re_Gpt_GetTimeRemaining, operation=P_IoHwAbGptLogical_GptTest.GetTimeRemaining
        IoHwAb_Ev_IoHwAbGptLogical_GptTest_DisableNotification: start-on-event=IoHwAb_Re_Gpt_DisableNotification, operation=P_IoHwAbGptLogical_GptTest.DisableNotification
        IoHwAb_Ev_IoHwAbGptLogical_GptTest_EnableNotification: start-on-event=IoHwAb_Re_Gpt_EnableNotification, operation=P_IoHwAbGptLogical_GptTest.EnableNotification
        IoHwAb_Ev_AmberIND1_SetDutyCycle: start-on-event=IoHwAb_Re_Pwm_SetDutyCycle, operation=P_AmberIND1.SetDutyCycle
        IoHwAb_Ev_AmberIND1_SetPeriodAndDuty: start-on-event=IoHwAb_Re_Pwm_SetPeriodAndDuty, operation=P_AmberIND1.SetPeriodAndDuty
        IoHwAb_Ev_AmberIND1_SetOutputToIdle: start-on-event=IoHwAb_Re_Pwm_SetOutputToIdle, operation=P_AmberIND1.SetOutputToIdle
        IoHwAb_Ev_AmberIND1_GetOutputState: start-on-event=IoHwAb_Re_Pwm_GetOutputState, operation=P_AmberIND1.GetOutputState
        IoHwAb_Ev_AmberIND1_DisableNotification: start-on-event=IoHwAb_Re_Pwm_DisableNotification, operation=P_AmberIND1.DisableNotification
        IoHwAb_Ev_AmberIND1_EnableNotification: start-on-event=IoHwAb_Re_Pwm_EnableNotification, operation=P_AmberIND1.EnableNotification
        IoHwAb_Ev_AmberIND2_SetDutyCycle: start-on-event=IoHwAb_Re_Pwm_SetDutyCycle, operation=P_AmberIND2.SetDutyCycle
        IoHwAb_Ev_AmberIND2_SetPeriodAndDuty: start-on-event=IoHwAb_Re_Pwm_SetPeriodAndDuty, operation=P_AmberIND2.SetPeriodAndDuty
        IoHwAb_Ev_AmberIND2_SetOutputToIdle: start-on-event=IoHwAb_Re_Pwm_SetOutputToIdle, operation=P_AmberIND2.SetOutputToIdle
        IoHwAb_Ev_AmberIND2_GetOutputState: start-on-event=IoHwAb_Re_Pwm_GetOutputState, operation=P_AmberIND2.GetOutputState
        IoHwAb_Ev_AmberIND2_DisableNotification: start-on-event=IoHwAb_Re_Pwm_DisableNotification, operation=P_AmberIND2.DisableNotification
        IoHwAb_Ev_AmberIND2_EnableNotification: start-on-event=IoHwAb_Re_Pwm_EnableNotification, operation=P_AmberIND2.EnableNotification
        IoHwAb_Ev_FANPWM1_SetDutyCycle: start-on-event=IoHwAb_Re_Pwm_SetDutyCycle, operation=P_FANPWM1.SetDutyCycle
        IoHwAb_Ev_FANPWM1_SetPeriodAndDuty: start-on-event=IoHwAb_Re_Pwm_SetPeriodAndDuty, operation=P_FANPWM1.SetPeriodAndDuty
        IoHwAb_Ev_FANPWM1_SetOutputToIdle: start-on-event=IoHwAb_Re_Pwm_SetOutputToIdle, operation=P_FANPWM1.SetOutputToIdle
        IoHwAb_Ev_FANPWM1_GetOutputState: start-on-event=IoHwAb_Re_Pwm_GetOutputState, operation=P_FANPWM1.GetOutputState
        IoHwAb_Ev_FANPWM1_DisableNotification: start-on-event=IoHwAb_Re_Pwm_DisableNotification, operation=P_FANPWM1.DisableNotification
        IoHwAb_Ev_FANPWM1_EnableNotification: start-on-event=IoHwAb_Re_Pwm_EnableNotification, operation=P_FANPWM1.EnableNotification
        IoHwAb_Ev_FANPWM2_SetDutyCycle: start-on-event=IoHwAb_Re_Pwm_SetDutyCycle, operation=P_FANPWM2.SetDutyCycle
        IoHwAb_Ev_FANPWM2_SetPeriodAndDuty: start-on-event=IoHwAb_Re_Pwm_SetPeriodAndDuty, operation=P_FANPWM2.SetPeriodAndDuty
        IoHwAb_Ev_FANPWM2_SetOutputToIdle: start-on-event=IoHwAb_Re_Pwm_SetOutputToIdle, operation=P_FANPWM2.SetOutputToIdle
        IoHwAb_Ev_FANPWM2_GetOutputState: start-on-event=IoHwAb_Re_Pwm_GetOutputState, operation=P_FANPWM2.GetOutputState
        IoHwAb_Ev_FANPWM2_DisableNotification: start-on-event=IoHwAb_Re_Pwm_DisableNotification, operation=P_FANPWM2.DisableNotification
        IoHwAb_Ev_FANPWM2_EnableNotification: start-on-event=IoHwAb_Re_Pwm_EnableNotification, operation=P_FANPWM2.EnableNotification
        IoHwAb_Ev_GreenIND1_SetDutyCycle: start-on-event=IoHwAb_Re_Pwm_SetDutyCycle, operation=P_GreenIND1.SetDutyCycle
        IoHwAb_Ev_GreenIND1_SetPeriodAndDuty: start-on-event=IoHwAb_Re_Pwm_SetPeriodAndDuty, operation=P_GreenIND1.SetPeriodAndDuty
        IoHwAb_Ev_GreenIND1_SetOutputToIdle: start-on-event=IoHwAb_Re_Pwm_SetOutputToIdle, operation=P_GreenIND1.SetOutputToIdle
        IoHwAb_Ev_GreenIND1_GetOutputState: start-on-event=IoHwAb_Re_Pwm_GetOutputState, operation=P_GreenIND1.GetOutputState
        IoHwAb_Ev_GreenIND1_DisableNotification: start-on-event=IoHwAb_Re_Pwm_DisableNotification, operation=P_GreenIND1.DisableNotification
        IoHwAb_Ev_GreenIND1_EnableNotification: start-on-event=IoHwAb_Re_Pwm_EnableNotification, operation=P_GreenIND1.EnableNotification
        IoHwAb_Ev_GreenIND2_SetDutyCycle: start-on-event=IoHwAb_Re_Pwm_SetDutyCycle, operation=P_GreenIND2.SetDutyCycle
        IoHwAb_Ev_GreenIND2_SetPeriodAndDuty: start-on-event=IoHwAb_Re_Pwm_SetPeriodAndDuty, operation=P_GreenIND2.SetPeriodAndDuty
        IoHwAb_Ev_GreenIND2_SetOutputToIdle: start-on-event=IoHwAb_Re_Pwm_SetOutputToIdle, operation=P_GreenIND2.SetOutputToIdle
        IoHwAb_Ev_GreenIND2_GetOutputState: start-on-event=IoHwAb_Re_Pwm_GetOutputState, operation=P_GreenIND2.GetOutputState
        IoHwAb_Ev_GreenIND2_DisableNotification: start-on-event=IoHwAb_Re_Pwm_DisableNotification, operation=P_GreenIND2.DisableNotification
        IoHwAb_Ev_GreenIND2_EnableNotification: start-on-event=IoHwAb_Re_Pwm_EnableNotification, operation=P_GreenIND2.EnableNotification
      port-api-options:
        {enable-take-address=false, indirect-api=false, port-defined-argument-value{value=ChIdx:0, value-type=IoHwAb_IndexType}, port=P_BCAN_EN}
        {enable-take-address=false, indirect-api=false, port-defined-argument-value{value=ChIdx:1, value-type=IoHwAb_IndexType}, port=P_BCAN_ERR}
        {enable-take-address=false, indirect-api=false, port-defined-argument-value{value=ChIdx:2, value-type=IoHwAb_IndexType}, port=P_BCAN_RX}
        {enable-take-address=false, indirect-api=false, port-defined-argument-value{value=ChIdx:3, value-type=IoHwAb_IndexType}, port=P_BCAN_STB}
        {enable-take-address=false, indirect-api=false, port-defined-argument-value{value=ChIdx:4, value-type=IoHwAb_IndexType}, port=P_FAN1_PULSE}
        {enable-take-address=false, indirect-api=false, port-defined-argument-value{value=ChIdx:5, value-type=IoHwAb_IndexType}, port=P_FAN2_PULSE}
        {enable-take-address=false, indirect-api=false, port-defined-argument-value{value=ChIdx:6, value-type=IoHwAb_IndexType}, port=P_LCAN_EN}
        {enable-take-address=false, indirect-api=false, port-defined-argument-value{value=ChIdx:7, value-type=IoHwAb_IndexType}, port=P_LCAN_ERR}
        {enable-take-address=false, indirect-api=false, port-defined-argument-value{value=ChIdx:8, value-type=IoHwAb_IndexType}, port=P_LCAN_RX}
        {enable-take-address=false, indirect-api=false, port-defined-argument-value{value=ChIdx:9, value-type=IoHwAb_IndexType}, port=P_LCAN_STB}
        {enable-take-address=false, indirect-api=false, port-defined-argument-value{value=ChIdx:10, value-type=IoHwAb_IndexType}, port=P_NFC1_IRQ}
        {enable-take-address=false, indirect-api=false, port-defined-argument-value{value=ChIdx:11, value-type=IoHwAb_IndexType}, port=P_NFC1_WAKEUP}
        {enable-take-address=false, indirect-api=false, port-defined-argument-value{value=ChIdx:12, value-type=IoHwAb_IndexType}, port=P_NFC2_IRQ}
        {enable-take-address=false, indirect-api=false, port-defined-argument-value{value=ChIdx:13, value-type=IoHwAb_IndexType}, port=P_NFC2_WAKEUP}
        {enable-take-address=false, indirect-api=false, port-defined-argument-value{value=ChIdx:14, value-type=IoHwAb_IndexType}, port=P_VBAT_CTRL}
        {enable-take-address=false, indirect-api=false, port-defined-argument-value{value=ChIdx:15, value-type=IoHwAb_IndexType}, port=P_VBAT_SW_CTRL}
        {enable-take-address=false, indirect-api=false, port-defined-argument-value{value=ChIdx:16, value-type=IoHwAb_IndexType}, port=P_VCC33_CTRL}
        {enable-take-address=false, indirect-api=false, port-defined-argument-value{value=ChIdx:17, value-type=IoHwAb_IndexType}, port=P_WDT_CLEAR_PULSE}
        {enable-take-address=false, indirect-api=false, port-defined-argument-value{value=ChIdx:18, value-type=IoHwAb_IndexType}, port=P_WDT_EN}
        {enable-take-address=false, indirect-api=false, port-defined-argument-value{value=ChIdx:0, value-type=IoHwAb_IndexType}, port=P_IGN1_ADC}
        {enable-take-address=false, indirect-api=false, port-defined-argument-value{value=ChIdx:1, value-type=IoHwAb_IndexType}, port=P_VBAT_ADC}
        {enable-take-address=false, indirect-api=false, port-defined-argument-value{value=ChIdx:0, value-type=IoHwAb_IndexType}, port=P_IoHwAbGptLogical_GptTest}
        {enable-take-address=false, indirect-api=false, port-defined-argument-value{value=ChIdx:0, value-type=IoHwAb_IndexType}, port=P_AmberIND1}
        {enable-take-address=false, indirect-api=false, port-defined-argument-value{value=ChIdx:1, value-type=IoHwAb_IndexType}, port=P_AmberIND2}
        {enable-take-address=false, indirect-api=false, port-defined-argument-value{value=ChIdx:2, value-type=IoHwAb_IndexType}, port=P_FANPWM1}
        {enable-take-address=false, indirect-api=false, port-defined-argument-value{value=ChIdx:3, value-type=IoHwAb_IndexType}, port=P_FANPWM2}
        {enable-take-address=false, indirect-api=false, port-defined-argument-value{value=ChIdx:4, value-type=IoHwAb_IndexType}, port=P_GreenIND1}
        {enable-take-address=false, indirect-api=false, port-defined-argument-value{value=ChIdx:5, value-type=IoHwAb_IndexType}, port=P_GreenIND2}
      20 x runnable:
        IoHwAb_Re_DigDir_ReadDirect: can-be-invoked-concurrently=true, symbol=IoHwAb_DigDirReadDirect
        IoHwAb_Re_DigDir_WriteDirect: can-be-invoked-concurrently=true, symbol=IoHwAb_DigDirWriteDirect
        IoHwAb_Re_DigDir_SetToInput: can-be-invoked-concurrently=true, symbol=IoHwAb_DigDirSetToInput
        IoHwAb_Re_DigDir_SetToOutput: can-be-invoked-concurrently=true, symbol=IoHwAb_DigDirSetToOutput
        IoHwAb_Re_DigDir_IsInput: can-be-invoked-concurrently=true, symbol=IoHwAb_DigDirIsInput
        IoHwAb_Re_DigDir_IsOutput: can-be-invoked-concurrently=true, symbol=IoHwAb_DigDirIsOutput
        IoHwAb_Re_AnaInDir_ReadDirect: symbol=IoHwAb_AnaInDirReadDirect
        IoHwAb_Re_Gpt_StartTimer: can-be-invoked-concurrently=true, symbol=IoHwAb_GptStartTimer
        IoHwAb_Re_Gpt_StopTimer: can-be-invoked-concurrently=true, symbol=IoHwAb_GptStopTimer
        IoHwAb_Re_Gpt_GetTimeElapsed: can-be-invoked-concurrently=true, symbol=IoHwAb_GptGetTimeElapsed
        IoHwAb_Re_Gpt_GetTimeRemaining: can-be-invoked-concurrently=true, symbol=IoHwAb_GptGetTimeRemaining
        IoHwAb_Re_Gpt_DisableNotification: can-be-invoked-concurrently=true, symbol=IoHwAb_GptDisableNotification
        IoHwAb_Re_Gpt_EnableNotification: can-be-invoked-concurrently=true, symbol=IoHwAb_GptEnableNotification
        IoHwAb_Re_Gpt_GptChannelConfiguration_IoHwAbTest_Cbk_Cbk: can-be-invoked-concurrently=true, symbol=GptChannelConfiguration_IoHwAbTest_Cbk
          sync call IoHwAb_Cp_Gpt_IoHwAbGptLogical_GptTest_Cbk: operation=R_IoHwAbGptLogical_GptTest_Cbk.Notification, timeout=0.0
        IoHwAb_Re_Pwm_SetDutyCycle: can-be-invoked-concurrently=true, symbol=IoHwAb_PwmSetDutyCycle
        IoHwAb_Re_Pwm_SetPeriodAndDuty: can-be-invoked-concurrently=true, symbol=IoHwAb_PwmSetPeriodAndDuty
        IoHwAb_Re_Pwm_SetOutputToIdle: can-be-invoked-concurrently=true, symbol=IoHwAb_PwmSetOutputToIdle
        IoHwAb_Re_Pwm_GetOutputState: can-be-invoked-concurrently=true, symbol=IoHwAb_PwmGetOutputState
        IoHwAb_Re_Pwm_DisableNotification: can-be-invoked-concurrently=true, symbol=IoHwAb_PwmDisableNotification
        IoHwAb_Re_Pwm_EnableNotification: can-be-invoked-concurrently=true, symbol=IoHwAb_PwmEnableNotification
  swc implementation SwcImplementation_IoHwAb: swc-bsw-mapping=SwcBswMapping_IoHwAb, behavior=IB_IoHwAb
